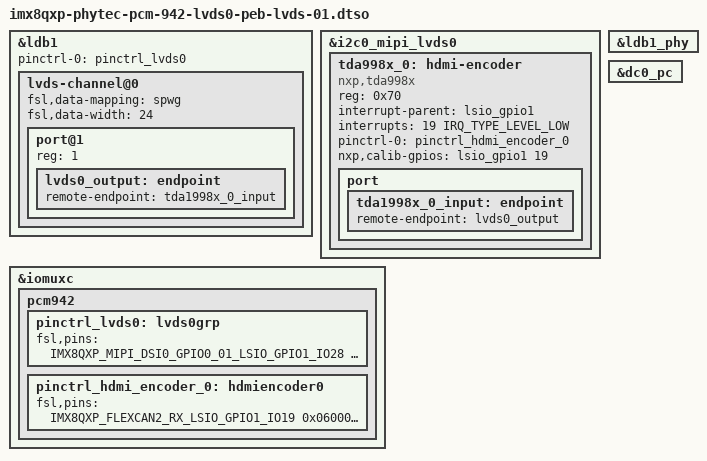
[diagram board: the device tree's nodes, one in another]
// SPDX-License-Identifier: GPL-2.0+
/*
 * Copyright (C) 2020-2021 PHYTEC America, LLC
 *
 * Enable LVDS to HDMI Adaptor on PCM-942
 */

/dts-v1/;
/plugin/;

#include <dt-bindings/pinctrl/pads-imx8qxp.h>
#include <dt-bindings/interrupt-controller/irq.h>
#include <dt-bindings/display/tda998x.h>

&ldb1 {
	pinctrl-names = "default";
	pinctrl-0 = <&pinctrl_lvds0>;
	status = "okay";

	lvds-channel@0 {
		#address-cells = <1>;
		#size-cells = <0>;
		fsl,data-mapping = "spwg";
		fsl,data-width = <24>;
		status = "okay";

		port@1 {
			reg = <1>;

			lvds0_output: endpoint {
				remote-endpoint = <&tda1998x_0_input>;
			};
		};
	};
};

&i2c0_mipi_lvds0 {
	#address-cells = <1>;
	#size-cells = <0>;
	status = "okay";

	tda998x_0: hdmi-encoder {
		status = "okay";
		compatible = "nxp,tda998x";
		reg = <0x70>;
		interrupt-parent = <&lsio_gpio1>;
		interrupts = <19 IRQ_TYPE_LEVEL_LOW>;
		pinctrl-0 = <&pinctrl_hdmi_encoder_0>;
		pinctrl-names = "default";
		nxp,calib-gpios = <&lsio_gpio1 19 0>;

		port {
			tda1998x_0_input: endpoint {
				remote-endpoint = <&lvds0_output>;
			};
		};
	};
};

&ldb1_phy {
	status = "okay";
};

&dc0_pc {	/* Pixel combiner */
	status = "okay";
};

&iomuxc {
	pcm942 {
		pinctrl_lvds0: lvds0grp {
			fsl,pins = <
				IMX8QXP_MIPI_DSI0_GPIO0_01_LSIO_GPIO1_IO28 0x06000021
			>;
		};

		pinctrl_hdmi_encoder_0: hdmiencoder0 {
			fsl,pins = <
				IMX8QXP_FLEXCAN2_RX_LSIO_GPIO1_IO19 0x06000021
			>;
		};
	};
};
